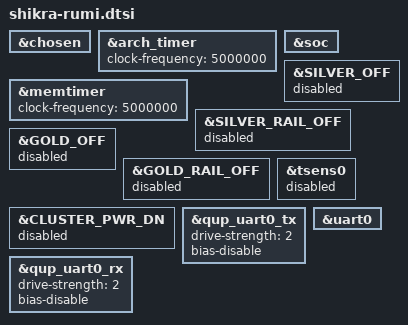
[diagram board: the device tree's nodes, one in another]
// SPDX-License-Identifier: BSD-3-Clause
/*
 * Copyright (c) Qualcomm Technologies, Inc. and/or its subsidiaries.
 */
&chosen {
};

&arch_timer {
	clock-frequency = <5000000>;
};

&memtimer {
	clock-frequency = <5000000>;
};

&soc {
};

&SILVER_OFF {
	status = "disabled";
};

&SILVER_RAIL_OFF {
	status = "disabled";
};

&GOLD_OFF {
	status = "disabled";
};

&GOLD_RAIL_OFF {
	status = "disabled";
};

&CLUSTER_PWR_DN {
	status = "disabled";
};

&tsens0 {
	status = "disabled";
};

&qup_uart0_tx {
	drive-strength = <2>;
	bias-disable;
};

&qup_uart0_rx {
	drive-strength = <2>;
	bias-disable;
};

&uart0 {
	status = "okay";
};
